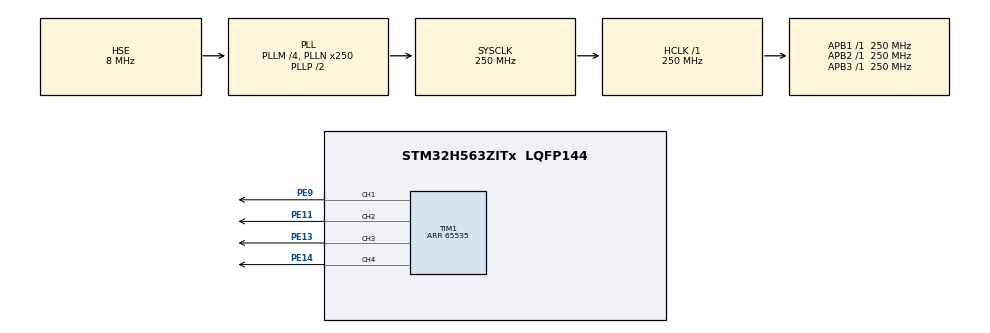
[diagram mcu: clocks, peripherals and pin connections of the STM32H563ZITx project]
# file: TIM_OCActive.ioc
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CORTEX_M33_NS.userName=CORTEX_M33
Mcu.Family=STM32H5
Mcu.Name=STM32H563ZITx
Mcu.Package=LQFP144
NVIC.PriorityGroup=NVIC_PRIORITYGROUP_4
PE11.GPIO_PuPd=GPIO_PULLUP
PE11.GPIO_Speed=GPIO_SPEED_FREQ_VERY_HIGH
PE11.Signal=S_TIM1_CH2
PE13.GPIO_PuPd=GPIO_PULLUP
PE13.GPIO_Speed=GPIO_SPEED_FREQ_VERY_HIGH
PE13.Signal=S_TIM1_CH3
PE14.GPIO_PuPd=GPIO_PULLUP
PE14.GPIO_Speed=GPIO_SPEED_FREQ_VERY_HIGH
PE14.Signal=S_TIM1_CH4
PE9.GPIO_PuPd=GPIO_PULLUP
PE9.GPIO_Speed=GPIO_SPEED_FREQ_VERY_HIGH
PE9.Signal=S_TIM1_CH1
PH0-OSC_IN(PH0).Mode=HSE-DIG-External-Clock-Source
PH0-OSC_IN(PH0).Signal=RCC_OSC_IN
ProjectManager.HeapSize=0x200
ProjectManager.StackSize=0x400
ProjectManager.TargetToolchain=EWARM V9.20
RCC.ADCFreq_Value=250000000
RCC.AHBFreq_Value=250000000
RCC.APB1Freq_Value=250000000
RCC.APB1TimFreq_Value=250000000
RCC.APB2Freq_Value=250000000
RCC.APB2TimFreq_Value=250000000
RCC.APB3Freq_Value=250000000
RCC.CSI_VALUE=4000000
RCC.CortexFreq_Value=250000000
RCC.EPOD_VALUE=8000000
RCC.HCLKFreq_Value=250000000
RCC.HSE_VALUE=8000000
RCC.HSI48_VALUE=48000000
RCC.HSIDiv=RCC_HSI_DIV1
RCC.HSI_VALUE=64000000
RCC.LSE_VALUE=32768
RCC.LSIRC_VALUE=32000
RCC.PLLM=4
RCC.PLLN=250
RCC.PLLSourceVirtual=RCC_PLL1_SOURCE_HSE
RCC.SYSCLKFreq_VALUE=250000000
RCC.SYSCLKSource=RCC_SYSCLKSOURCE_PLLCLK
RCC.USBFreq_Value=48000000
RCC.VCOOutputFreq_Value=500000000
SH.S_TIM1_CH1.0=TIM1_CH1,Output Compare1 CH1
SH.S_TIM1_CH2.0=TIM1_CH2,Output Compare2 CH2
SH.S_TIM1_CH3.0=TIM1_CH3,Output Compare3 CH3
SH.S_TIM1_CH4.0=TIM1_CH4,Output Compare4 CH4
TIM1.AutoReloadPreload=TIM_AUTORELOAD_PRELOAD_DISABLE
TIM1.AutomaticOutput=TIM_AUTOMATICOUTPUT_DISABLE
TIM1.Break2Filter=0
TIM1.Break2Polarity=TIM_BREAK2POLARITY_HIGH
TIM1.Break2State=TIM_BREAK2_DISABLE
TIM1.BreakFilter=0
TIM1.BreakPolarity=TIM_BREAKPOLARITY_HIGH
TIM1.BreakState=TIM_BREAK_DISABLE
TIM1.Channel-Output\ Compare1\ CH1=TIM_CHANNEL_1
TIM1.Channel-Output\ Compare2\ CH2=TIM_CHANNEL_2
TIM1.Channel-Output\ Compare3\ CH3=TIM_CHANNEL_3
TIM1.Channel-Output\ Compare4\ CH4=TIM_CHANNEL_4
TIM1.ClearInputSource=TIM_CLEARINPUTSOURCE_NONE
TIM1.ClockDivision=TIM_CLOCKDIVISION_DIV1
TIM1.CounterMode=TIM_COUNTERMODE_UP
TIM1.LockLevel=TIM_LOCKLEVEL_OFF
TIM1.OC1Preload=DISABLE
TIM1.OC2Preload=DISABLE
TIM1.OC3Preload=DISABLE
TIM1.OC4Preload=DISABLE
TIM1.OCIdleState_1=TIM_OCIDLESTATE_RESET
TIM1.OCIdleState_2=TIM_OCIDLESTATE_RESET
TIM1.OCIdleState_3=TIM_OCIDLESTATE_RESET
TIM1.OCIdleState_4=TIM_OCIDLESTATE_RESET
TIM1.OCMode_1=TIM_OCMODE_ACTIVE
TIM1.OCMode_2=TIM_OCMODE_ACTIVE
TIM1.OCMode_3=TIM_OCMODE_ACTIVE
TIM1.OCMode_4=TIM_OCMODE_ACTIVE
TIM1.OCPolarity_1=TIM_OCPOLARITY_HIGH
TIM1.OCPolarity_2=TIM_OCPOLARITY_HIGH
TIM1.OCPolarity_3=TIM_OCPOLARITY_HIGH
TIM1.OCPolarity_4=TIM_OCPOLARITY_HIGH
TIM1.OffStateIDLEMode=TIM_OSSI_DISABLE
TIM1.OffStateRunMode=TIM_OSSR_DISABLE
TIM1.Period=65535
TIM1.Prescaler=PRESCALER_VALUE
TIM1.PulseNoDither_1=PULSE1_VALUE
TIM1.PulseNoDither_2=PULSE2_VALUE
TIM1.PulseNoDither_3=PULSE3_VALUE
TIM1.PulseNoDither_4=PULSE4_VALUE
TIM1.RepetitionCounter=0
TIM1.TIM_MasterOutputTrigger=TIM_TRGO_RESET
TIM1.TIM_MasterOutputTrigger2=TIM_TRGO2_RESET
TIM1.TIM_MasterSlaveMode=TIM_MASTERSLAVEMODE_DISABLE
VP_ICACHE_VS_ICACHE.Mode=DefaultMode
VP_PWR_VS_SECSignals.Mode=Security/Privilege
board=custom

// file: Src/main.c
/* USER CODE BEGIN Header */
/**
  ******************************************************************************
  * @file    TIM/TIM_OCActive/Src/main.c
  * @author  MCD Application Team
  * @brief   This example shows how to configure the Timer to generate four
  *          delayed signals.
  ******************************************************************************
  * @attention
  *
  * Copyright (c) 2023 STMicroelectronics.
  * All rights reserved.
  *
  * This software is licensed under terms that can be found in the LICENSE file
  * in the root directory of this software component.
  * If no LICENSE file comes with this software, it is provided AS-IS.
  *
  ******************************************************************************
  */
/* USER CODE END Header */
#include "main.h"

TIM_HandleTypeDef htim1;

void SystemClock_Config(void);
static void MX_GPIO_Init(void);
static void MX_ICACHE_Init(void);
static void MX_TIM1_Init(void);

int main(void)
{

  /* USER CODE BEGIN 1 */
  /* STM32H5xx HAL library initialization:
       - Systick timer is configured by default as source of time base, but user
             can eventually implement his proper time base source (a general purpose
             timer for example or other time source), keeping in mind that Time base
             duration should be kept 1ms since PPP_TIMEOUT_VALUEs are defined and
             handled in milliseconds basis.
       - Set NVIC Group Priority to 4
       - Low Level Initialization
     */
  /* USER CODE END 1 */

  /* MCU Configuration--------------------------------------------------------*/

  /* Reset of all peripherals, Initializes the Flash interface and the Systick. */
  HAL_Init();

  /* Configure the system clock */
  SystemClock_Config();

  /* USER CODE BEGIN SysInit */

  /* Configure LED1, LED3 */
  BSP_LED_Init(LED1);
  BSP_LED_Init(LED3);

  /* USER CODE END SysInit */

  /* Initialize all configured peripherals */
  MX_GPIO_Init();
  MX_ICACHE_Init();
  MX_TIM1_Init();
  /* USER CODE BEGIN 2 */

  /*## Turn On LED1: use PB0 rising edge as reference ####################*/
  /* Turn on LED1 */
  BSP_LED_On(LED1);

  /*## Start signals generation #######################################*/
  /* Start channel 1 in Output compare mode */
  if(HAL_TIM_OC_Start(&htim1, TIM_CHANNEL_1) != HAL_OK)
  {
    /* Starting Error */
    Error_Handler();
  }
  /* Start channel 2 in Output compare mode */
  if(HAL_TIM_OC_Start(&htim1, TIM_CHANNEL_2) != HAL_OK)
  {
    /* Starting Error */
    Error_Handler();
  }
  /* Start channel 3 in Output compare mode */
  if(HAL_TIM_OC_Start(&htim1, TIM_CHANNEL_3) != HAL_OK)
  {
    /* Starting Error */
    Error_Handler();
  }
  /* Start channel 4 in Output compare mode */
  if(HAL_TIM_OC_Start(&htim1, TIM_CHANNEL_4) != HAL_OK)
  {
    /* Starting Error */
    Error_Handler();
  }
  /* USER CODE END 2 */

  /* Infinite loop */
  while (1)
  {

  }
}

void SystemClock_Config(void)
{
  RCC_OscInitTypeDef RCC_OscInitStruct = {0};
  RCC_ClkInitTypeDef RCC_ClkInitStruct = {0};

  /** Configure the main internal regulator output voltage
  */
  __HAL_PWR_VOLTAGESCALING_CONFIG(PWR_REGULATOR_VOLTAGE_SCALE0);

  while(!__HAL_PWR_GET_FLAG(PWR_FLAG_VOSRDY)) {}

  /** Initializes the RCC Oscillators according to the specified parameters
  * in the RCC_OscInitTypeDef structure.
  */
  RCC_OscInitStruct.OscillatorType = RCC_OSCILLATORTYPE_HSE;
  RCC_OscInitStruct.HSEState = RCC_HSE_BYPASS_DIGITAL;
  RCC_OscInitStruct.PLL.PLLState = RCC_PLL_ON;
  RCC_OscInitStruct.PLL.PLLSource = RCC_PLL1_SOURCE_HSE;
  RCC_OscInitStruct.PLL.PLLM = 4;
  RCC_OscInitStruct.PLL.PLLN = 250;
  RCC_OscInitStruct.PLL.PLLP = 2;
  RCC_OscInitStruct.PLL.PLLQ = 2;
  RCC_OscInitStruct.PLL.PLLR = 2;
  RCC_OscInitStruct.PLL.PLLRGE = RCC_PLL1_VCIRANGE_1;
  RCC_OscInitStruct.PLL.PLLVCOSEL = RCC_PLL1_VCORANGE_WIDE;
  RCC_OscInitStruct.PLL.PLLFRACN = 0;
  if (HAL_RCC_OscConfig(&RCC_OscInitStruct) != HAL_OK)
  {
    Error_Handler();
  }

  /** Initializes the CPU, AHB and APB buses clocks
  */
  RCC_ClkInitStruct.ClockType = RCC_CLOCKTYPE_HCLK|RCC_CLOCKTYPE_SYSCLK
                              |RCC_CLOCKTYPE_PCLK1|RCC_CLOCKTYPE_PCLK2
                              |RCC_CLOCKTYPE_PCLK3;
  RCC_ClkInitStruct.SYSCLKSource = RCC_SYSCLKSOURCE_PLLCLK;
  RCC_ClkInitStruct.AHBCLKDivider = RCC_SYSCLK_DIV1;
  RCC_ClkInitStruct.APB1CLKDivider = RCC_HCLK_DIV1;
  RCC_ClkInitStruct.APB2CLKDivider = RCC_HCLK_DIV1;
  RCC_ClkInitStruct.APB3CLKDivider = RCC_HCLK_DIV1;

  if (HAL_RCC_ClockConfig(&RCC_ClkInitStruct, FLASH_LATENCY_5) != HAL_OK)
  {
    Error_Handler();
  }

  /** Configure the programming delay
  */
  __HAL_FLASH_SET_PROGRAM_DELAY(FLASH_PROGRAMMING_DELAY_2);
}

static void MX_ICACHE_Init(void)
{

  /** Enable instruction cache (default 2-ways set associative cache)
  */
  if (HAL_ICACHE_Enable() != HAL_OK)
  {
    Error_Handler();
  }

}

static void MX_TIM1_Init(void)
{

  TIM_MasterConfigTypeDef sMasterConfig = {0};
  TIM_OC_InitTypeDef sConfigOC = {0};
  TIM_BreakDeadTimeConfigTypeDef sBreakDeadTimeConfig = {0};

  htim1.Instance = TIM1;
  htim1.Init.Prescaler = PRESCALER_VALUE;
  htim1.Init.CounterMode = TIM_COUNTERMODE_UP;
  htim1.Init.Period = 65535;
  htim1.Init.ClockDivision = TIM_CLOCKDIVISION_DIV1;
  htim1.Init.RepetitionCounter = 0;
  htim1.Init.AutoReloadPreload = TIM_AUTORELOAD_PRELOAD_DISABLE;
  if (HAL_TIM_OC_Init(&htim1) != HAL_OK)
  {
    Error_Handler();
  }
  sMasterConfig.MasterOutputTrigger = TIM_TRGO_RESET;
  sMasterConfig.MasterOutputTrigger2 = TIM_TRGO2_RESET;
  sMasterConfig.MasterSlaveMode = TIM_MASTERSLAVEMODE_DISABLE;
  if (HAL_TIMEx_MasterConfigSynchronization(&htim1, &sMasterConfig) != HAL_OK)
  {
    Error_Handler();
  }
  sConfigOC.OCMode = TIM_OCMODE_ACTIVE;
  sConfigOC.Pulse = PULSE1_VALUE;
  sConfigOC.OCPolarity = TIM_OCPOLARITY_HIGH;
  sConfigOC.OCNPolarity = TIM_OCNPOLARITY_HIGH;
  sConfigOC.OCFastMode = TIM_OCFAST_DISABLE;
  sConfigOC.OCIdleState = TIM_OCIDLESTATE_RESET;
  sConfigOC.OCNIdleState = TIM_OCNIDLESTATE_RESET;
  if (HAL_TIM_OC_ConfigChannel(&htim1, &sConfigOC, TIM_CHANNEL_1) != HAL_OK)
  {
    Error_Handler();
  }
  sConfigOC.Pulse = PULSE2_VALUE;
  if (HAL_TIM_OC_ConfigChannel(&htim1, &sConfigOC, TIM_CHANNEL_2) != HAL_OK)
  {
    Error_Handler();
  }
  sConfigOC.Pulse = PULSE3_VALUE;
  if (HAL_TIM_OC_ConfigChannel(&htim1, &sConfigOC, TIM_CHANNEL_3) != HAL_OK)
  {
    Error_Handler();
  }
  sConfigOC.Pulse = PULSE4_VALUE;
  if (HAL_TIM_OC_ConfigChannel(&htim1, &sConfigOC, TIM_CHANNEL_4) != HAL_OK)
  {
    Error_Handler();
  }
  sBreakDeadTimeConfig.OffStateRunMode = TIM_OSSR_DISABLE;
  sBreakDeadTimeConfig.OffStateIDLEMode = TIM_OSSI_DISABLE;
  sBreakDeadTimeConfig.LockLevel = TIM_LOCKLEVEL_OFF;
  sBreakDeadTimeConfig.DeadTime = 0;
  sBreakDeadTimeConfig.BreakState = TIM_BREAK_DISABLE;
  sBreakDeadTimeConfig.BreakPolarity = TIM_BREAKPOLARITY_HIGH;
  sBreakDeadTimeConfig.BreakFilter = 0;
  sBreakDeadTimeConfig.BreakAFMode = TIM_BREAK_AFMODE_INPUT;
  sBreakDeadTimeConfig.Break2State = TIM_BREAK2_DISABLE;
  sBreakDeadTimeConfig.Break2Polarity = TIM_BREAK2POLARITY_HIGH;
  sBreakDeadTimeConfig.Break2Filter = 0;
  sBreakDeadTimeConfig.Break2AFMode = TIM_BREAK_AFMODE_INPUT;
  sBreakDeadTimeConfig.AutomaticOutput = TIM_AUTOMATICOUTPUT_DISABLE;
  if (HAL_TIMEx_ConfigBreakDeadTime(&htim1, &sBreakDeadTimeConfig) != HAL_OK)
  {
    Error_Handler();
  }
  HAL_TIM_MspPostInit(&htim1);

}

static void MX_GPIO_Init(void)
{

  /* GPIO Ports Clock Enable */
  __HAL_RCC_GPIOH_CLK_ENABLE();
  __HAL_RCC_GPIOE_CLK_ENABLE();

}

void Error_Handler(void)
{
  /* USER CODE BEGIN Error_Handler_Debug */
  /* LED3 is slowly blinking (1 sec. period) */
  while(1)
  {
    BSP_LED_Toggle(LED3);
    HAL_Delay(1000);
  }
  /* USER CODE END Error_Handler_Debug */
}
